AUTOSAR XML (schema 4-2-2)
package /ComponentTypes
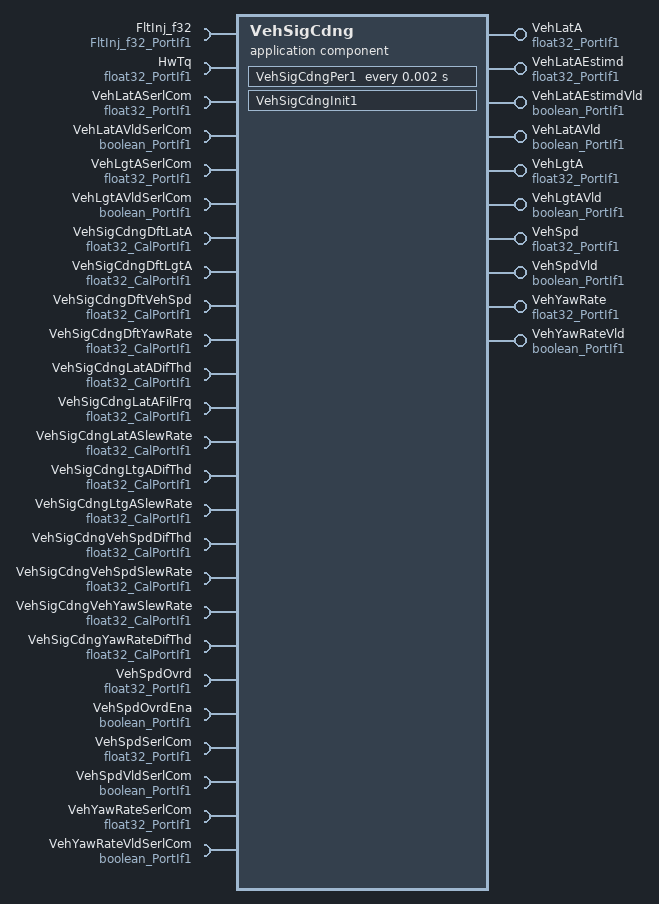
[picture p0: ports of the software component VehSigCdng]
  application sw component type VehSigCdng
    10 x provide port:
      VehLatA: nonqueued-sender-com-spec{data-element=Val, init-value=0}, provided-interface=float32_PortIf1
      VehLatAEstimd: nonqueued-sender-com-spec{data-element=Val, init-value=0}, provided-interface=float32_PortIf1
      VehLatAEstimdVld: nonqueued-sender-com-spec{data-element=Logl, init-value=0}, provided-interface=boolean_PortIf1
      VehLatAVld: nonqueued-sender-com-spec{data-element=Logl, init-value=0}, provided-interface=boolean_PortIf1
      VehLgtA: nonqueued-sender-com-spec{data-element=Val, init-value=0}, provided-interface=float32_PortIf1
      VehLgtAVld: nonqueued-sender-com-spec{data-element=Logl, init-value=0}, provided-interface=boolean_PortIf1
      VehSpd: nonqueued-sender-com-spec{data-element=Val, init-value=0}, provided-interface=float32_PortIf1
      VehSpdVld: nonqueued-sender-com-spec{data-element=Logl, init-value=0}, provided-interface=boolean_PortIf1
      VehYawRate: nonqueued-sender-com-spec{data-element=Val, init-value=0}, provided-interface=float32_PortIf1
      VehYawRateVld: nonqueued-sender-com-spec{data-element=Logl, init-value=0}, provided-interface=boolean_PortIf1
    25 x require port:
      FltInj_f32: client-com-spec=Oper, required-interface=FltInj_f32_PortIf1
      HwTq: nonqueued-receiver-com-spec{data-element=Val, filter=data-filter-type=ALWAYS, init-value=0}, required-interface=float32_PortIf1
      VehLatASerlCom: nonqueued-receiver-com-spec{data-element=Val, filter=data-filter-type=ALWAYS, init-value=0}, required-interface=float32_PortIf1
      VehLatAVldSerlCom: nonqueued-receiver-com-spec{data-element=Logl, filter=data-filter-type=ALWAYS, init-value=0}, required-interface=boolean_PortIf1
      VehLgtASerlCom: nonqueued-receiver-com-spec{data-element=Val, filter=data-filter-type=ALWAYS, init-value=0}, required-interface=float32_PortIf1
      VehLgtAVldSerlCom: nonqueued-receiver-com-spec{data-element=Logl, filter=data-filter-type=ALWAYS, init-value=0}, required-interface=boolean_PortIf1
      VehSigCdngDftLatA: parameter-require-com-spec{init-value=0, parameter=Val}, required-interface=float32_CalPortIf1
      VehSigCdngDftLgtA: parameter-require-com-spec{init-value=0, parameter=Val}, required-interface=float32_CalPortIf1
      VehSigCdngDftVehSpd: parameter-require-com-spec{init-value=100, parameter=Val}, required-interface=float32_CalPortIf1
      VehSigCdngDftYawRate: parameter-require-com-spec{init-value=0, parameter=Val}, required-interface=float32_CalPortIf1
      VehSigCdngLatADifThd: parameter-require-com-spec{init-value=0.2, parameter=Val}, required-interface=float32_CalPortIf1
      VehSigCdngLatAFilFrq: parameter-require-com-spec{init-value=100, parameter=Val}, required-interface=float32_CalPortIf1
      VehSigCdngLatASlewRate: parameter-require-com-spec{init-value=10, parameter=Val}, required-interface=float32_CalPortIf1
      VehSigCdngLtgADifThd: parameter-require-com-spec{init-value=1, parameter=Val}, required-interface=float32_CalPortIf1
      VehSigCdngLtgASlewRate: parameter-require-com-spec{init-value=50, parameter=Val}, required-interface=float32_CalPortIf1
      VehSigCdngVehSpdDifThd: parameter-require-com-spec{init-value=5, parameter=Val}, required-interface=float32_CalPortIf1
      VehSigCdngVehSpdSlewRate: parameter-require-com-spec{init-value=50, parameter=Val}, required-interface=float32_CalPortIf1
      VehSigCdngVehYawSlewRate: parameter-require-com-spec{init-value=120, parameter=Val}, required-interface=float32_CalPortIf1
      VehSigCdngYawRateDifThd: parameter-require-com-spec{init-value=20, parameter=Val}, required-interface=float32_CalPortIf1
      VehSpdOvrd: nonqueued-receiver-com-spec{data-element=Val, filter=data-filter-type=ALWAYS, init-value=100}, required-interface=float32_PortIf1
      VehSpdOvrdEna: nonqueued-receiver-com-spec{data-element=Logl, filter=data-filter-type=ALWAYS, init-value=0}, required-interface=boolean_PortIf1
      VehSpdSerlCom: nonqueued-receiver-com-spec{data-element=Val, filter=data-filter-type=ALWAYS, init-value=0}, required-interface=float32_PortIf1
      VehSpdVldSerlCom: nonqueued-receiver-com-spec{data-element=Logl, filter=data-filter-type=ALWAYS, init-value=0}, required-interface=boolean_PortIf1
      VehYawRateSerlCom: nonqueued-receiver-com-spec{data-element=Val, filter=data-filter-type=ALWAYS, init-value=0}, required-interface=float32_PortIf1
      VehYawRateVldSerlCom: nonqueued-receiver-com-spec{data-element=Logl, filter=data-filter-type=ALWAYS, init-value=0}, required-interface=boolean_PortIf1
    behavior VehSigCdng_InternalBehavior
      ar-typed-per-instance-memorys:
        10 x data, all with sw-calibration-access=READ-ONLY:
          HwTqFilRec: type=FilLpRec1
          LatAFilRec: type=FilLpRec1
          PrevLatA: type=float32
          PrevLatAVld: type=boolean
          PrevLtgA: type=float32
          PrevLtgAVld: type=boolean
          PrevVehSpd: type=float32
          PrevVehSpdVld: type=boolean
          PrevYawRate: type=float32
          PrevYawRateVld: type=boolean
      init event VehSigCdng_InitEvent: start-on-event=VehSigCdngInit1
      timing event TMT_VehSigCdngPer1: start-on-event=VehSigCdngPer1, period=0.002
      port-api-options:
        enable-take-address=false, error-handling=NO-TRANSFORMER-ERROR-HANDLING, indirect-api=false, port=FltInj_f32
        enable-take-address=false, error-handling=NO-TRANSFORMER-ERROR-HANDLING, indirect-api=false, port=HwTq
        enable-take-address=false, error-handling=NO-TRANSFORMER-ERROR-HANDLING, indirect-api=false, port=VehLatAEstimdVld
        enable-take-address=false, error-handling=NO-TRANSFORMER-ERROR-HANDLING, indirect-api=false, port=VehLatAVld
        enable-take-address=false, error-handling=NO-TRANSFORMER-ERROR-HANDLING, indirect-api=false, port=VehLatAVldSerlCom
        enable-take-address=false, error-handling=NO-TRANSFORMER-ERROR-HANDLING, indirect-api=false, port=VehLgtAVld
        enable-take-address=false, error-handling=NO-TRANSFORMER-ERROR-HANDLING, indirect-api=false, port=VehLgtAVldSerlCom
        enable-take-address=false, error-handling=NO-TRANSFORMER-ERROR-HANDLING, indirect-api=false, port=VehSigCdngDftLatA
        enable-take-address=false, error-handling=NO-TRANSFORMER-ERROR-HANDLING, indirect-api=false, port=VehSigCdngDftLgtA
        enable-take-address=false, error-handling=NO-TRANSFORMER-ERROR-HANDLING, indirect-api=false, port=VehSigCdngDftVehSpd
        enable-take-address=false, error-handling=NO-TRANSFORMER-ERROR-HANDLING, indirect-api=false, port=VehSigCdngLatADifThd
        enable-take-address=false, error-handling=NO-TRANSFORMER-ERROR-HANDLING, indirect-api=false, port=VehSigCdngLatAFilFrq
        enable-take-address=false, error-handling=NO-TRANSFORMER-ERROR-HANDLING, indirect-api=false, port=VehSigCdngLtgADifThd
        enable-take-address=false, error-handling=NO-TRANSFORMER-ERROR-HANDLING, indirect-api=false, port=VehSigCdngLtgASlewRate
        enable-take-address=false, error-handling=NO-TRANSFORMER-ERROR-HANDLING, indirect-api=false, port=VehSigCdngVehSpdDifThd
        enable-take-address=false, error-handling=NO-TRANSFORMER-ERROR-HANDLING, indirect-api=false, port=VehSigCdngVehSpdSlewRate
        enable-take-address=false, error-handling=NO-TRANSFORMER-ERROR-HANDLING, indirect-api=false, port=VehSigCdngVehYawSlewRate
        enable-take-address=false, error-handling=NO-TRANSFORMER-ERROR-HANDLING, indirect-api=false, port=VehSigCdngYawRateDifThd
        enable-take-address=false, error-handling=NO-TRANSFORMER-ERROR-HANDLING, indirect-api=false, port=VehSpd
        enable-take-address=false, error-handling=NO-TRANSFORMER-ERROR-HANDLING, indirect-api=false, port=VehSpdSerlCom
        enable-take-address=false, error-handling=NO-TRANSFORMER-ERROR-HANDLING, indirect-api=false, port=VehYawRate
        enable-take-address=false, error-handling=NO-TRANSFORMER-ERROR-HANDLING, indirect-api=false, port=VehYawRateSerlCom
        enable-take-address=false, error-handling=NO-TRANSFORMER-ERROR-HANDLING, indirect-api=false, port=VehYawRateVld
        enable-take-address=false, error-handling=NO-TRANSFORMER-ERROR-HANDLING, indirect-api=false, port=VehYawRateVldSerlCom
      runnable VehSigCdngInit1
      runnable VehSigCdngPer1
        data-receive-point-by-arguments:
          11 x access:
            REC_HwTq_Val: accessed-variable=HwTq.Val
            REC_VehLatASerlCom_Val: accessed-variable=VehLatASerlCom.Val
            REC_VehLatAVldSerlCom_Logl: accessed-variable=VehLatAVldSerlCom.Logl
            REC_VehLgtASerlCom_Val: accessed-variable=VehLgtASerlCom.Val
            REC_VehLgtAVldSerlCom_Logl: accessed-variable=VehLgtAVldSerlCom.Logl
            REC_VehSpdOvrd_Val: accessed-variable=VehSpdOvrd.Val
            REC_VehSpdOvrdEna_Logl: accessed-variable=VehSpdOvrdEna.Logl
            REC_VehSpdSerlCom_Val: accessed-variable=VehSpdSerlCom.Val
            REC_VehSpdVldSerlCom_Logl: accessed-variable=VehSpdVldSerlCom.Logl
            REC_VehYawRateSerlCom_Val: accessed-variable=VehYawRateSerlCom.Val
            REC_VehYawRateVldSerlCom_Logl: accessed-variable=VehYawRateVldSerlCom.Logl
        data-send-points:
          10 x access:
            SEND_VehLatA_Val: accessed-variable=VehLatA.Val
            SEND_VehLatAEstimd_Val: accessed-variable=VehLatAEstimd.Val
            SEND_VehLatAEstimdVld_Logl: accessed-variable=VehLatAEstimdVld.Logl
            SEND_VehLatAVld_Logl: accessed-variable=VehLatAVld.Logl
            SEND_VehLgtA_Val: accessed-variable=VehLgtA.Val
            SEND_VehLgtAVld_Logl: accessed-variable=VehLgtAVld.Logl
            SEND_VehSpd_Val: accessed-variable=VehSpd.Val
            SEND_VehSpdVld_Logl: accessed-variable=VehSpdVld.Logl
            SEND_VehYawRate_Val: accessed-variable=VehYawRate.Val
            SEND_VehYawRateVld_Logl: accessed-variable=VehYawRateVld.Logl
        sync call SC_FltInj_f32_Oper: operation=FltInj_f32.Oper, timeout=0
  swc implementation VehSigCdng_Implementation: behavior=VehSigCdng_InternalBehavior
    code-descriptors:
      code Default: artifact-descriptors=autosar-engineering-object={short-label=Default, category=SWSRC}
